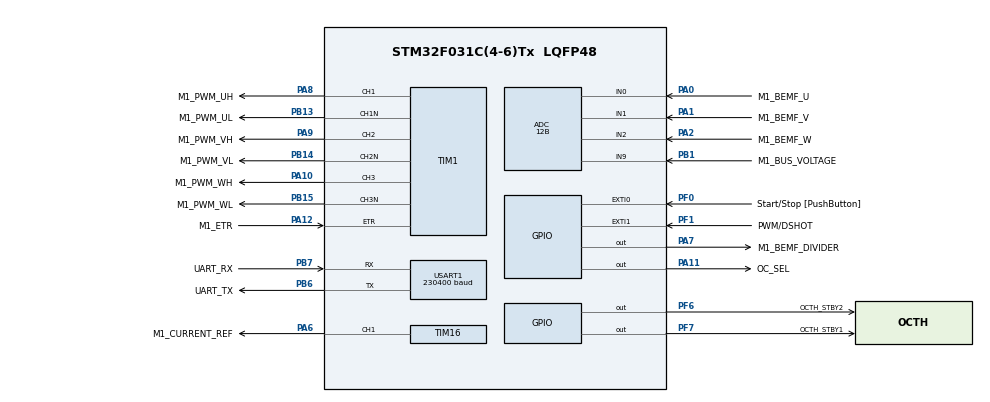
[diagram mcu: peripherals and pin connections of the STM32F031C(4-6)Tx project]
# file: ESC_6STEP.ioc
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ADC.ClockPrescaler=ADC_CLOCK_ASYNC_DIV1
ADC.ContinuousConvMode=DISABLE
ADC.DMAContinuousRequests=DISABLE
ADC.DataAlign=ADC_DATAALIGN_LEFT
ADC.DiscontinuousConvMode=DISABLE
ADC.EOCSelection=ADC_EOC_SINGLE_CONV
ADC.EnableAnalogWatchDog=true
ADC.ExternalTrigConv=ADC_EXTERNALTRIGCONV_T1_TRGO
ADC.ExternalTrigConvEdge=ADC_EXTERNALTRIGCONVEDGE_FALLING
ADC.LowPowerAutoPowerOff=DISABLE
ADC.LowPowerAutoWait=DISABLE
ADC.Overrun=ADC_OVR_DATA_PRESERVED
ADC.Resolution=ADC_RESOLUTION_12B
ADC.SamplingTime=ADC_SAMPLETIME_7CYCLES_5
ADC.ScanConvMode=ADC_SCAN_DIRECTION_FORWARD
ADC.WatchdogChannel=ADC_CHANNEL_0
ADC.WatchdogMode=ADC_ANALOGWATCHDOG_SINGLE_REG
Dma.Request0=USART1_RX
Dma.Request1=USART1_TX
Dma.USART1_RX.0.Direction=DMA_PERIPH_TO_MEMORY
Dma.USART1_RX.0.Instance=DMA1_Channel3
Dma.USART1_RX.0.MemDataAlignment=DMA_MDATAALIGN_BYTE
Dma.USART1_RX.0.MemInc=DMA_MINC_ENABLE
Dma.USART1_RX.0.Mode=DMA_NORMAL
Dma.USART1_RX.0.PeriphDataAlignment=DMA_PDATAALIGN_BYTE
Dma.USART1_RX.0.PeriphInc=DMA_PINC_DISABLE
Dma.USART1_RX.0.Priority=DMA_PRIORITY_LOW
Dma.USART1_TX.1.Direction=DMA_MEMORY_TO_PERIPH
Dma.USART1_TX.1.Instance=DMA1_Channel2
Dma.USART1_TX.1.MemDataAlignment=DMA_MDATAALIGN_BYTE
Dma.USART1_TX.1.MemInc=DMA_MINC_ENABLE
Dma.USART1_TX.1.Mode=DMA_NORMAL
Dma.USART1_TX.1.PeriphDataAlignment=DMA_PDATAALIGN_BYTE
Dma.USART1_TX.1.PeriphInc=DMA_PINC_DISABLE
Dma.USART1_TX.1.Priority=DMA_PRIORITY_LOW
ExtraMW=MotorControl
ExtraMW.MotorControl.Config=MotorControl
ExtraMW.MotorControl.Mode=MotorControl
ExtraMW.MotorControl.Root=MCSDK_v6.3.2-Full/MotorControl
ExtraMW.MotorControl.Template=templates
Mcu.Family=STM32F0
Mcu.Name=STM32F031C(4-6)Tx
Mcu.Package=LQFP48
MotorControl.ADC_REFERENCE_VOLTAGE=3.3
MotorControl.BEMF_ADC_SAMPLING_TIME=7
MotorControl.BEMF_ADC_TRIG_TIME_DPP=921
MotorControl.BEMF_ADC_TRIG_TIME_ON_DPP=256
MotorControl.BEMF_AVERAGING_FIFO_DEPTH=8
MotorControl.BEMF_DIVIDER_AVAILABLE=true
MotorControl.BEMF_DIVIDER_GPIO_PIN=LL_GPIO_PIN_7
MotorControl.BEMF_DIVIDER_GPIO_PORT=GPIOA
MotorControl.BEMF_ON_SENSING_DIVIDER=5.545455
MotorControl.BEMF_PWM_ON_ENABLE_HYSTERESIS_DPP=51
MotorControl.BEMF_PWM_ON_ENABLE_THRES_DPP=716
MotorControl.BOARD=STEVAL-SPIN3202
MotorControl.BUS_VOLTAGE_READING=true
MotorControl.CCMRAM_ENABLED=false
MotorControl.CLOCK_FREQUENCY=CPU_CLK_48_MHZ
MotorControl.CLOCK_SOURCE=INTERNAL
MotorControl.CPU_CLK_48_MHZ=true
MotorControl.CTLBOARD_NAME=STEVAL-SPIN3202
MotorControl.CUBE_MX_VER=6.8.1
MotorControl.CURRENT_LIMITER_OFFSET=true
MotorControl.CURR_REF_DIVIDER=3.2
MotorControl.CURR_REF_ETR_GPIO_PIN=LL_GPIO_PIN_12
MotorControl.CURR_REF_ETR_GPIO_PORT=GPIOA
MotorControl.CURR_REF_ETR_POLARITY=ACTIVE_HIGH
MotorControl.CURR_REF_GPIO_PIN=LL_GPIO_PIN_6
MotorControl.CURR_REF_GPIO_PORT=GPIOA
MotorControl.CURR_REF_OC_SEL_GPIO_LABEL=OC_SEL
MotorControl.CURR_REF_OC_SEL_GPIO_PIN=LL_GPIO_PIN_11
MotorControl.CURR_REF_OC_SEL_GPIO_PORT=GPIOA
MotorControl.CURR_REF_TIMER_SELECTION=TIM16
MotorControl.DEBUG_DAC_FUNCTIONALITY_EN=false
MotorControl.DRIVES_NUMBER_SELECTION=SINGLEDRIVE
MotorControl.DRIVE_MODE=CM
MotorControl.DRIVE_NUMBER=1
MotorControl.DRIVE_TYPE=SIX_STEP
MotorControl.ENCODER_AVAILABLE=false
MotorControl.ENCODER_PPR=400
MotorControl.EXT_CLOCK_FREQUENCY=INT_RC_OSC
MotorControl.FAST_DEMAG=false
MotorControl.FLASH_SIZE=32
MotorControl.HALL_SENSORS_AVAILABLE=false
MotorControl.HIGH_SIDE_IDLE_STATE=false
MotorControl.HWV_CM=InternalCurrentLimiter_PWM_IntRef
MotorControl.HWV_PWM=PoweringHighAndLowSides
MotorControl.HW_COMPLEMENTED_LOW_SIDE=false
MotorControl.HW_DEAD_TIME_NS=1000
MotorControl.INT_RC_OSC=true
MotorControl.IPs=NVIC,RCC,SYS,MotorControl,TIM1,TIM2,ADC,TIM16,USART1,DMA
MotorControl.LF_TIMER_SELECTION=LF_TIM2
MotorControl.LOW_MEMORY_FOOTPRINT_REG=false
MotorControl.LOW_SIDE_IDLE_STATE=false
MotorControl.LOW_SIDE_SIGNALS_ENABLING=LS_PWM_TIMER
MotorControl.M1_ADC_AWD_FILTER_NUMBER=0
MotorControl.M1_AMPLIFICATION_GAIN=6.6
MotorControl.M1_AUXILIARY_SPEED_SENSOR=NONE
MotorControl.M1_BEMF_THRESHOLD_PWM=50
MotorControl.M1_BEMF_THRESHOLD_PWM_HIGH=100
MotorControl.M1_BEMF_THRESHOLD_PWM_LOW=1
MotorControl.M1_BOARD_MAX_CURRENT=15
MotorControl.M1_BUS_VOLTAGE_READING=true
MotorControl.M1_COMMUTATION_STEP_TIME_BUF_SIZE=12
MotorControl.M1_COMPUTATION_DELAY=-1
MotorControl.M1_DBG_OPEN_LOOP_ENABLE=false
MotorControl.M1_DC_CURRENT_RS_MEAS=15
MotorControl.M1_DEFAULT_TARGET_SPEED_RPM=4500
MotorControl.M1_DP_TOPOLOGY=NONE
MotorControl.M1_DRIVE_TYPE=SIX_STEP
MotorControl.M1_ENABLE_SL_ALGO_FROM_PHASE=3
MotorControl.M1_ENCODER_PPR=400
MotorControl.M1_HALL_PHASE_SHIFT=300
MotorControl.M1_HALL_SENSORS_PLACEMENT=DEGREES_120
MotorControl.M1_HIGH_SIDE_IDLE_STATE=false
MotorControl.M1_HW_DEAD_TIME_NS=1000
MotorControl.M1_ICL_ENABLED=false
MotorControl.M1_ID_DEMAG=-15
MotorControl.M1_LDLQ_RATIO=1.000
MotorControl.M1_LOW_SIDE_IDLE_STATE=false
MotorControl.M1_LOW_SIDE_SIGNALS_ENABLING=LS_PWM_TIMER
MotorControl.M1_LS=0.000018
MotorControl.M1_MAX_APPLICATION_SPEED=8000
MotorControl.M1_MIN_APPLICATION_SPEED=0
MotorControl.M1_MOTOR_MAX_SPEED_RPM=8000
MotorControl.M1_MOTOR_NAME=Bull Running BR2804-1700
MotorControl.M1_MOTOR_RATED_FLUX=0.006998542
MotorControl.M1_MOTOR_VOLTAGE_CONSTANT=1.0
MotorControl.M1_NB_CONSECUTIVE_TESTS=10
MotorControl.M1_NOMINAL_BUS_VOLTAGE_V=12
MotorControl.M1_NOMINAL_CURRENT=15
MotorControl.M1_OBS_MINIMUM_SPEED_RPM=800
MotorControl.M1_OCP_TOPOLOGY=NONE
MotorControl.M1_ON_OVER_VOLTAGE=TURN_OFF_PWM
MotorControl.M1_OVP_THRESHOLD_HIGH=14
MotorControl.M1_OV_VOLTAGE_PROT_ENABLING=true
MotorControl.M1_OV_VOLTAGE_THRESHOLD_V=14
MotorControl.M1_PHASE1_DURATION=500
MotorControl.M1_PHASE1_FINAL_CURRENT=3
MotorControl.M1_PHASE1_FINAL_SPEED_RPM=0
MotorControl.M1_PHASE2_DURATION=1000
MotorControl.M1_PHASE2_FINAL_CURRENT=3
MotorControl.M1_PHASE2_FINAL_SPEED_RPM=1000
MotorControl.M1_PHASE3_DURATION=500
MotorControl.M1_PHASE3_FINAL_CURRENT=3
MotorControl.M1_PHASE3_FINAL_SPEED_RPM=1000
MotorControl.M1_PHASE4_DURATION=0
MotorControl.M1_PHASE4_FINAL_CURRENT=3
MotorControl.M1_PHASE4_FINAL_SPEED_RPM=0
MotorControl.M1_PHASE5_DURATION=0
MotorControl.M1_PHASE5_FINAL_CURRENT=3
MotorControl.M1_PHASE5_FINAL_SPEED_RPM=0
MotorControl.M1_PID_SPEED_KD_DEFAULT=0
MotorControl.M1_PID_SPEED_KI_DEFAULT=3
MotorControl.M1_PID_SPEED_KP_DEFAULT=2196
MotorControl.M1_POLE_PAIR_NUM=7
MotorControl.M1_POTENTIOMETER_ENABLE=false
MotorControl.M1_POWERBOARD_NAME=STEVAL-SPIN3202
MotorControl.M1_PWM_CHARGE_BOOT_CAP_DUTY_CYCLES=0.000
MotorControl.M1_PWM_CHARGE_BOOT_CAP_MS=10
MotorControl.M1_PWM_DRIVER_PN=STSPIN32F0A
MotorControl.M1_PWM_FREQUENCY=75000
MotorControl.M1_PWM_TIMER_BRK_IRQ=TIM1_BRK_UP_TRG_COM
MotorControl.M1_PWM_TIMER_SELECTION=PWM_TIM1
MotorControl.M1_PWM_TIMER_UP_IRQ=TIM1_BRK_UP_TRG_COM
MotorControl.M1_REGULATION_EXECUTION_RATE=2
MotorControl.M1_RS=0.11
MotorControl.M1_RSHUNT=0.01
MotorControl.M1_SHARED_SIGNAL_ENABLE=false
MotorControl.M1_SPD_DIFFERENTIAL_TERM_ENABLING=false
MotorControl.M1_SPEED_BAND_LOWER_LIMIT=15
MotorControl.M1_SPEED_BAND_UPPER_LIMIT=17
MotorControl.M1_SPEED_LOOP_FREQUENCY_HZ=1000
MotorControl.M1_SPEED_SENSOR=SENSORLESS_ADC
MotorControl.M1_SP_KDDIV=16
MotorControl.M1_SP_KIDIV=16384
MotorControl.M1_SP_KPDIV=16384
MotorControl.M1_SS_MEAS_ERRORS_BEFORE_FAULTS=3
MotorControl.M1_STARTING_ANGLE_DEG=0
MotorControl.M1_SW_DEADTIME_NS=850
MotorControl.M1_TEMPERATURE_READING=false
MotorControl.M1_TRANSITION_DURATION=25
MotorControl.M1_UD_VOLTAGE_THRESHOLD_V=7
MotorControl.M1_UV_VOLTAGE_PROT_ENABLING=true
MotorControl.M1_VBUS_ADC=ADC1
MotorControl.M1_VBUS_ADC_SAMPLING_TIME=28
MotorControl.M1_VBUS_CHANNEL=ADC_CHANNEL_9
MotorControl.M1_VBUS_PARTITIONING_FACTOR=0.052164840897235255
MotorControl.M1_ZCD_FALLING_TO_COMM=30
MotorControl.M1_ZCD_RISING_TO_COMM=30
MotorControl.MCP_ASPEP_OVER_UART=true
MotorControl.MCP_ASYNC_EN=false
MotorControl.MCP_ASYNC_OVER_ASPEP_EN=false
MotorControl.MCP_ASYNC_OVER_UART_A_EN=false
MotorControl.MCP_DMACH_RX_UART_A=3
MotorControl.MCP_DMACH_TX_UART_A=2
MotorControl.MCP_DMA_RX_UART_A=DMA1
MotorControl.MCP_DMA_TX_UART_A=DMA1
MotorControl.MCP_EN=true
MotorControl.MCP_IRQ_HANDLER_DMA_RX_UART_A=DMA1_Channel2_3_IRQHandler
MotorControl.MCP_IRQ_HANDLER_UART_A=USART1_IRQHandler
MotorControl.MCP_OVER_ASPEP_EN=true
MotorControl.MCP_OVER_STLNK_EN=false
MotorControl.MCP_OVER_UART_A_EN=true
MotorControl.MCP_OVER_UART_B_EN=false
MotorControl.MCP_RX_SYNC_PAYLOAD_MAX=128
MotorControl.MCP_TX_SYNC_PAYLOAD_MAX=128
MotorControl.MCU=STSPIN32F0A
MotorControl.MCU_FAMILY=STM32F0
MotorControl.MCU_LINE=STM32F0x1
MotorControl.MCU_NAME=STM32F031C(4-6)Tx
MotorControl.MCU_PACKAGE=LQFP48
MotorControl.MCU_TYPE=STSPIN32F0A
MotorControl.MCU_USERNAME=STM32F031C6Tx
MotorControl.MC_WORKBENCH_VERSION=6.3.2
MotorControl.MIN_DEMAG_TIME=3
MotorControl.MOTOR_TYPE=PMSM
MotorControl.OCP_INT_REF=250
MotorControl.ON_OVER_VOLTAGE=TURN_OFF_PWM
MotorControl.OV_VOLTAGE_PROT_ENABLING=true
MotorControl.PHASE_UH_GPIO_PIN=LL_GPIO_PIN_8
MotorControl.PHASE_UH_GPIO_PORT=GPIOA
MotorControl.PHASE_UH_POLARITY=H_ACTIVE_HIGH
MotorControl.PHASE_UL_GPIO_PIN=LL_GPIO_PIN_13
MotorControl.PHASE_UL_GPIO_PORT=GPIOB
MotorControl.PHASE_UL_POLARITY=L_ACTIVE_HIGH
MotorControl.PHASE_U_BEMF_ADC=ADC1
MotorControl.PHASE_U_BEMF_CHANNEL=ADC_CHANNEL_0
MotorControl.PHASE_U_BEMF_GPIO_PIN=LL_GPIO_PIN_0
MotorControl.PHASE_U_BEMF_GPIO_PORT=GPIOA
MotorControl.PHASE_U_PWM_CHANNEL=TIM_Channel_1
MotorControl.PHASE_VH_GPIO_PIN=LL_GPIO_PIN_9
MotorControl.PHASE_VH_GPIO_PORT=GPIOA
MotorControl.PHASE_VH_POLARITY=H_ACTIVE_HIGH
MotorControl.PHASE_VL_GPIO_PIN=LL_GPIO_PIN_14
MotorControl.PHASE_VL_GPIO_PORT=GPIOB
MotorControl.PHASE_VL_POLARITY=L_ACTIVE_HIGH
MotorControl.PHASE_V_BEMF_ADC=ADC1
MotorControl.PHASE_V_BEMF_CHANNEL=ADC_CHANNEL_1
MotorControl.PHASE_V_BEMF_GPIO_PIN=LL_GPIO_PIN_1
MotorControl.PHASE_V_BEMF_GPIO_PORT=GPIOA
MotorControl.PHASE_V_PWM_CHANNEL=TIM_Channel_2
MotorControl.PHASE_WH_GPIO_PIN=LL_GPIO_PIN_10
MotorControl.PHASE_WH_GPIO_PORT=GPIOA
MotorControl.PHASE_WH_POLARITY=H_ACTIVE_HIGH
MotorControl.PHASE_WL_GPIO_PIN=LL_GPIO_PIN_15
MotorControl.PHASE_WL_GPIO_PORT=GPIOB
MotorControl.PHASE_WL_POLARITY=L_ACTIVE_HIGH
MotorControl.PHASE_W_BEMF_ADC=ADC1
MotorControl.PHASE_W_BEMF_CHANNEL=ADC_CHANNEL_2
MotorControl.PHASE_W_BEMF_GPIO_PIN=LL_GPIO_PIN_2
MotorControl.PHASE_W_BEMF_GPIO_PORT=GPIOA
MotorControl.PHASE_W_PWM_CHANNEL=TIM_Channel_3
MotorControl.POTENTIOMETER_READING=false
MotorControl.PWM_FREQUENCY=75000
MotorControl.PWM_TIMER_SELECTION=PWM_TIM1
MotorControl.QUASI_SYNC=false
MotorControl.REF_TIMER_FREQUENCY=60000
MotorControl.REGULATION_EXECUTION_RATE=2
MotorControl.RUN_DEMAG_TIME=20
MotorControl.R_BRAKE_SWITCH_OFF_THRES_V=12
MotorControl.SENSORLESS_ADC=true
MotorControl.SINGLEDRIVE=true
MotorControl.SPD_DIFFERENTIAL_TERM_ENABLING=false
MotorControl.SPEED_SENSOR_SELECTION=SENSORLESS_ADC
MotorControl.SPEED_THRESHOLD_DEMAG=3000
MotorControl.STARTUP_DEMAG_TIME=20
MotorControl.START_STOP_BTN=true
MotorControl.START_STOP_GPIO_PIN=LL_GPIO_PIN_0
MotorControl.START_STOP_GPIO_PORT=GPIOF
MotorControl.START_STOP_POLARITY=DIN_ACTIVE_LOW
MotorControl.START_STOP_POLARITY_EDGE=GPIO_PULLUP
MotorControl.STSPIN32F0A=true
MotorControl.SW_DEADTIME_NS=850
MotorControl.TEMPERATURE_READING=false
MotorControl.TFDIFFERENTIAL_TERM_ENABLING=false
MotorControl.USART_RX_GPIO_PIN=LL_GPIO_PIN_7
MotorControl.USART_RX_GPIO_PORT=GPIOB
MotorControl.USART_SELECTION=USE_USART1
MotorControl.USART_SELECTION_A=USART1
MotorControl.USART_SPEED=1843200
MotorControl.USART_TX_GPIO_PIN=LL_GPIO_PIN_6
MotorControl.USART_TX_GPIO_PORT=GPIOB
MotorControl.UV_VOLTAGE_PROT_ENABLING=true
MotorControl.VBUS_ADC=ADC1
MotorControl.VBUS_ADC_SAMPLING_TIME=28
MotorControl.VBUS_CHANNEL=ADC_CHANNEL_9
MotorControl.VBUS_GPIO_PIN=LL_GPIO_PIN_1
MotorControl.VBUS_GPIO_PORT=GPIOB
MotorControl.WB_MX_ADC_AWD_FILTER_NUMBER=NONE
MotorControl.WB_MX_PHASE_U_BEMF_ADC_IRQ=ADC1
MotorControl.WB_MX_PHASE_V_BEMF_ADC_IRQ=ADC1
MotorControl.WB_MX_PHASE_W_BEMF_ADC_IRQ=ADC1
MotorControl.WB_UI_CURR_REF_TIMER_CHANNEL=CH1
MotorControl.WB_UI_ENCODER_HAS_INDEX_PIN=false
MotorControl.WB_UI_FRICTION=0.437
MotorControl.WB_UI_IMAX=22.6
MotorControl.WB_UI_INERTIA=0.348
MotorControl.WB_UI_MAGNETIC_STRUCTURE=SM-PMSM
MotorControl.WB_UI_MAX_CURRENT=15
MotorControl.WB_UI_MAX_NOMINAL_DC_VOLTAGE=12
MotorControl.WB_UI_MAX_PWMFREQUENCY=100000
MotorControl.WB_UI_MAX_READABLE_CURRENT=7.576
MotorControl.WB_UI_MOTOR_DESCRIPTION=External rotor type - 7 poles pairs brushless - DC motor
MotorControl.WB_UI_PWM_ON_SENSING=true
MotorControl.WB_UI_PW_BOARD_MAX_RATED_CURRENT=15
MotorControl.WB_UI_PW_BOARD_MAX_VOLTAGE=45
MotorControl.WB_UI_PW_BOARD_MIN_VOLTAGE=6.7
MotorControl.WB_to_Mx_template_version=24-04-17
MotorControl.WB_to_Mx_version=6.2.3
NVIC.ADC1_IRQn=true\:0\:0\:true\:true\:false\:5\:true\:true\:true
NVIC.DMA1_Channel2_3_IRQn=true\:3\:0\:true\:true\:false\:2\:true\:true\:true
NVIC.EXTI0_1_IRQn=true\:3\:0\:false\:true\:false\:6\:true\:true\:true
NVIC.TIM1_BRK_UP_TRG_COM_IRQn=true\:1\:0\:false\:true\:false\:4\:true\:true\:true
NVIC.TIM2_IRQn=true\:0\:0\:true\:true\:false\:3\:true\:true\:true
NVIC.USART1_IRQn=true\:3\:0\:true\:true\:false\:1\:true\:true\:true
PA0.GPIO_Label=M1_BEMF_U
PA0.Mode=IN0
PA0.Signal=ADC_IN0
PA1.GPIO_Label=M1_BEMF_V
PA1.Mode=IN1
PA1.Signal=ADC_IN1
PA10.GPIO_Label=M1_PWM_WH
PA10.GPIO_PuPd=GPIO_PULLDOWN
PA10.GPIO_Speed=GPIO_SPEED_FREQ_HIGH
PA10.Signal=S_TIM1_CH3
PA11.GPIO_Label=OC_SEL
PA11.GPIO_PuPd=GPIO_PULLDOWN
PA11.PinState=GPIO_PIN_SET
PA11.Signal=GPIO_Output
PA12.GPIO_Label=M1_ETR
PA12.Signal=S_TIM1_ETR
PA13.GPIO_Label=TMS
PA13.Mode=Serial_Wire
PA13.Signal=SYS_SWDIO
PA14.GPIO_Label=TCK
PA14.Mode=Serial_Wire
PA14.Signal=SYS_SWCLK
PA2.GPIO_Label=M1_BEMF_W
PA2.Mode=IN2
PA2.Signal=ADC_IN2
PA6.GPIO_Label=M1_CURRENT_REF
PA6.Signal=S_TIM16_CH1
PA7.GPIO_Label=M1_BEMF_DIVIDER
PA7.GPIO_PuPd=GPIO_PULLDOWN
PA7.PinState=GPIO_PIN_RESET
PA7.Signal=GPIO_Output
PA8.GPIO_Label=M1_PWM_UH
PA8.GPIO_PuPd=GPIO_PULLDOWN
PA8.GPIO_Speed=GPIO_SPEED_FREQ_HIGH
PA8.Signal=S_TIM1_CH1
PA9.GPIO_Label=M1_PWM_VH
PA9.GPIO_PuPd=GPIO_PULLDOWN
PA9.GPIO_Speed=GPIO_SPEED_FREQ_HIGH
PA9.Signal=S_TIM1_CH2
PB1.GPIO_Label=M1_BUS_VOLTAGE
PB1.Mode=IN9
PB1.Signal=ADC_IN9
PB13.GPIO_Label=M1_PWM_UL
PB13.GPIO_PuPd=GPIO_PULLDOWN
PB13.GPIO_Speed=GPIO_SPEED_FREQ_HIGH
PB13.Mode=PWM Generation1 CH1 CH1N
PB13.Signal=TIM1_CH1N
PB14.GPIO_Label=M1_PWM_VL
PB14.GPIO_PuPd=GPIO_PULLDOWN
PB14.GPIO_Speed=GPIO_SPEED_FREQ_HIGH
PB14.Mode=PWM Generation2 CH2 CH2N
PB14.Signal=TIM1_CH2N
PB15.GPIO_Label=M1_PWM_WL
PB15.GPIO_PuPd=GPIO_PULLDOWN
PB15.GPIO_Speed=GPIO_SPEED_FREQ_HIGH
PB15.Mode=PWM Generation3 CH3 CH3N
PB15.Signal=TIM1_CH3N
PB6.GPIO_Label=UART_TX
PB6.GPIO_Mode=GPIO_MODE_AF_PP
PB6.GPIO_PuPd=GPIO_NOPULL
PB6.GPIO_Speed=GPIO_SPEED_FREQ_LOW
PB6.Mode=Asynchronous
PB6.Signal=USART1_TX
PB7.GPIO_Label=UART_RX
PB7.GPIO_Mode=GPIO_MODE_AF_PP
PB7.GPIO_PuPd=GPIO_NOPULL
PB7.GPIO_Speed=GPIO_SPEED_FREQ_LOW
PB7.Mode=Asynchronous
PB7.Signal=USART1_RX
PF0-OSC_IN.GPIO_Label=Start/Stop [PushButton]
PF0-OSC_IN.GPIO_ModeDefaultEXTI=GPIO_MODE_IT_FALLING
PF0-OSC_IN.GPIO_PuPd=GPIO_PULLUP
PF0-OSC_IN.Signal=GPXTI0
PF1-OSC_OUT.GPIO_Label=PWM/DSHOT
PF1-OSC_OUT.GPIO_ModeDefaultEXTI=GPIO_MODE_IT_RISING_FALLING
PF1-OSC_OUT.GPIO_PuPd=GPIO_PULLDOWN
PF1-OSC_OUT.Signal=GPXTI1
PF6.GPIO_Label=OCTH_STBY2
PF6.GPIO_PuPd=GPIO_PULLDOWN
PF6.PinState=GPIO_PIN_SET
PF6.Signal=GPIO_Output
PF7.GPIO_Label=OCTH_STBY1
PF7.GPIO_PuPd=GPIO_PULLDOWN
PF7.PinState=GPIO_PIN_RESET
PF7.Signal=GPIO_Output
ProjectManager.HeapSize=0x80
ProjectManager.StackSize=0x400
ProjectManager.TargetToolchain=STM32CubeIDE
RCC.AHBFreq_Value=48000000
RCC.APB1Freq_Value=48000000
RCC.APB1TimFreq_Value=48000000
RCC.HCLKFreq_Value=48000000
RCC.PLLDivider=RCC_PREDIV_DIV2
RCC.PLLMUL=RCC_PLL_MUL12
RCC.PREFETCH_ENABLE=1
RCC.SYSCLKFreq_VALUE=48000000
RCC.SYSCLKSource=RCC_SYSCLKSOURCE_PLLCLK
SH.S_TIM16_CH1.0=TIM16_CH1,PWM Generation1 CH1
SH.S_TIM1_CH1.0=TIM1_CH1,PWM Generation1 CH1 CH1N
SH.S_TIM1_CH2.0=TIM1_CH2,PWM Generation2 CH2 CH2N
SH.S_TIM1_CH3.0=TIM1_CH3,PWM Generation3 CH3 CH3N
SH.S_TIM1_ETR.0=TIM1_ETR,ETR-as-clearing-source
TIM1.AutoReloadPreload=TIM_AUTORELOAD_PRELOAD_DISABLE
TIM1.AutomaticOutput=TIM_AUTOMATICOUTPUT_DISABLE
TIM1.BreakPolarity=TIM_BREAKPOLARITY_LOW
TIM1.BreakState=TIM_BREAK_DISABLE
TIM1.Channel-PWM\ Generation1\ CH1\ CH1N=TIM_CHANNEL_1
TIM1.Channel-PWM\ Generation2\ CH2\ CH2N=TIM_CHANNEL_2
TIM1.Channel-PWM\ Generation3\ CH3\ CH3N=TIM_CHANNEL_3
TIM1.Channel-PWM\ Generation4\ No\ Output=TIM_CHANNEL_4
TIM1.ClearChannel1=TIM_CHANNEL_1
TIM1.ClearChannel2=TIM_CHANNEL_2
TIM1.ClearChannel3=TIM_CHANNEL_3
TIM1.ClearInputPolarity=TIM_CLEARINPUTPOLARITY_NONINVERTED
TIM1.ClearInputSource=TIM_CLEARINPUTSOURCE_ETR
TIM1.ClockDivision=TIM_CLOCKDIVISION_DIV1
TIM1.CounterMode=TIM_COUNTERMODE_UP
TIM1.DeadTime=((DEAD_TIME_COUNTS) / 2)
TIM1.LockLevel=TIM_LOCKLEVEL_OFF
TIM1.OC1Preload_PWM=ENABLE
TIM1.OC2Preload_PWM=ENABLE
TIM1.OC3Preload_PWM=ENABLE
TIM1.OC4Preload_PWM=ENABLE
TIM1.OCIdleState_1=TIM_OCIDLESTATE_RESET
TIM1.OCIdleState_2=TIM_OCIDLESTATE_RESET
TIM1.OCIdleState_3=TIM_OCIDLESTATE_RESET
TIM1.OCIdleState_4=TIM_OCIDLESTATE_RESET
TIM1.OCMode_PWM-PWM\ Generation1\ CH1\ CH1N=TIM_OCMODE_PWM1
TIM1.OCMode_PWM-PWM\ Generation2\ CH2\ CH2N=TIM_OCMODE_PWM1
TIM1.OCMode_PWM-PWM\ Generation3\ CH3\ CH3N=TIM_OCMODE_PWM1
TIM1.OCMode_PWM-PWM\ Generation4\ No\ Output=TIM_OCMODE_PWM1
TIM1.OCNIdleState_1=TIM_OCNIDLESTATE_RESET
TIM1.OCNIdleState_2=TIM_OCNIDLESTATE_RESET
TIM1.OCNIdleState_3=TIM_OCNIDLESTATE_RESET
TIM1.OCNPolarity_1=TIM_OCNPOLARITY_HIGH
TIM1.OCNPolarity_2=TIM_OCNPOLARITY_HIGH
TIM1.OCNPolarity_3=TIM_OCNPOLARITY_HIGH
TIM1.OCPolarity_1=TIM_OCPOLARITY_HIGH
TIM1.OCPolarity_2=TIM_OCPOLARITY_HIGH
TIM1.OCPolarity_3=TIM_OCPOLARITY_HIGH
TIM1.OCPolarity_4=TIM_OCPOLARITY_HIGH
TIM1.OffStateIDLEMode=TIM_OSSI_ENABLE
TIM1.OffStateRunMode=TIM_OSSR_ENABLE
TIM1.Period=(PWM_PERIOD_CYCLES)
TIM1.Prescaler=((TIM_CLOCK_DIVIDER) - 1)
TIM1.RepetitionCounter=(REP_COUNTER)
TIM1.TIM_MasterOutputTrigger=TIM_TRGO_OC4REF
TIM1.TIM_MasterSlaveMode=TIM_MASTERSLAVEMODE_ENABLE
TIM16.Channel=TIM_CHANNEL_1
TIM16.Channel-PWM\ Generation1\ CH1=TIM_CHANNEL_1
TIM16.OCMode_PWM-PWM\ Generation1\ CH1=TIM_OCMODE_PWM1
TIM16.Period=PWM_PERIOD_CYCLES_REF
TIM16.Prescaler=((TIM_CLOCK_DIVIDER) - 1)
TIM2.Period=LF_TIMER_ARR
TIM2.Prescaler=LF_TIMER_PSC
TIM2.TIM_MasterOutputTrigger=TIM_TRGO_ENABLE
TIM2.TIM_MasterSlaveMode=TIM_MASTERSLAVEMODE_ENABLE
USART1.BaudRate=230400
USART1.VirtualMode-Asynchronous=VM_ASYNC
USART1.WordLength=WORDLENGTH_8B
VP_MotorControl_MC_ENABLED.Mode=SixStep
VP_TIM16_VS_ClockSourceINT.Mode=Enable_Timer
VP_TIM1_VS_no_output4.Mode=PWM Generation4 No Output
VP_TIM2_VS_ClockSourceINT.Mode=Internal
VP_TIM3_VS_ClockSourceINT.Mode=Internal
board=custom

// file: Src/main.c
/* USER CODE BEGIN Header */
/**
 ******************************************************************************
 * @file           : main.c
 * @brief          : Main program body
 ******************************************************************************
 * @attention
 *
 * Copyright (c) 2025 STMicroelectronics.
 * All rights reserved.
 *
 * This software is licensed under terms that can be found in the LICENSE file
 * in the root directory of this software component.
 * If no LICENSE file comes with this software, it is provided AS-IS.
 *
 ******************************************************************************
 */
/* USER CODE END Header */
#include "main.h"

/* USER CODE BEGIN Includes */
#include "communication.h"
#include "utils.h"
#include "interface.h"
/* USER CODE END Includes */

TIM_HandleTypeDef htim3;

void SystemClock_Config(void);
static void MX_GPIO_Init(void);
static void MX_DMA_Init(void);
static void MX_ADC_Init(void);
static void MX_TIM1_Init(void);
static void MX_TIM16_Init(void);
static void MX_TIM2_Init(void);
static void MX_USART1_UART_Init(void);
static void MX_TIM3_Init(void);
static void MX_NVIC_Init(void);

int main(void) {

	/* MCU Configuration--------------------------------------------------------*/

	/* Reset of all peripherals, Initializes the Flash interface and the Systick. */
	HAL_Init();

	/* Configure the system clock */
	SystemClock_Config();

	/* Initialize all configured peripherals */
	MX_GPIO_Init();
	MX_DMA_Init();
	MX_ADC_Init();
	MX_TIM1_Init();
	MX_TIM16_Init();
	MX_TIM2_Init();
	MX_USART1_UART_Init();
	MX_MotorControl_Init();
	MX_TIM3_Init();

	/* Initialize interrupts */
	MX_NVIC_Init();
	/* USER CODE BEGIN 2 */

	Interface_Init();
	Communication_TimerInit(PWM, &htim3);
	/* USER CODE END 2 */

	/* Infinite loop */
	while (1) {

		/* USER CODE BEGIN 3 */
		Communication_SetThrottle();
		Interface_ProcessData();
	}
	/* USER CODE END 3 */
}

void SystemClock_Config(void) {
	LL_FLASH_SetLatency(LL_FLASH_LATENCY_1);
	while (LL_FLASH_GetLatency() != LL_FLASH_LATENCY_1) {
	}
	LL_RCC_HSI_Enable();

	/* Wait till HSI is ready */
	while (LL_RCC_HSI_IsReady() != 1) {

	}
	LL_RCC_HSI_SetCalibTrimming(16);
	LL_RCC_HSI14_Enable();

	/* Wait till HSI14 is ready */
	while (LL_RCC_HSI14_IsReady() != 1) {

	}
	LL_RCC_HSI14_SetCalibTrimming(16);
	LL_RCC_PLL_ConfigDomain_SYS(LL_RCC_PLLSOURCE_HSI_DIV_2, LL_RCC_PLL_MUL_12);
	LL_RCC_PLL_Enable();

	/* Wait till PLL is ready */
	while (LL_RCC_PLL_IsReady() != 1) {

	}
	LL_RCC_SetAHBPrescaler(LL_RCC_SYSCLK_DIV_1);
	LL_RCC_SetAPB1Prescaler(LL_RCC_APB1_DIV_1);
	LL_RCC_SetSysClkSource(LL_RCC_SYS_CLKSOURCE_PLL);

	/* Wait till System clock is ready */
	while (LL_RCC_GetSysClkSource() != LL_RCC_SYS_CLKSOURCE_STATUS_PLL) {

	}
	LL_SetSystemCoreClock(48000000);

	/* Update the time base */
	if (HAL_InitTick(TICK_INT_PRIORITY) != HAL_OK) {
		Error_Handler();
	}
	LL_RCC_HSI14_EnableADCControl();
	LL_RCC_SetUSARTClockSource(LL_RCC_USART1_CLKSOURCE_PCLK1);
}

/**
 * @brief NVIC Configuration.
 * @retval None
 */
static void MX_NVIC_Init(void) {
	/* USART1_IRQn interrupt configuration */
	NVIC_SetPriority(USART1_IRQn, 3);
	NVIC_EnableIRQ(USART1_IRQn);
	/* DMA1_Channel2_3_IRQn interrupt configuration */
	NVIC_SetPriority(DMA1_Channel2_3_IRQn, 3);
	NVIC_EnableIRQ(DMA1_Channel2_3_IRQn);
	/* TIM2_IRQn interrupt configuration */
	NVIC_SetPriority(TIM2_IRQn, 0);
	NVIC_EnableIRQ(TIM2_IRQn);
	/* TIM1_BRK_UP_TRG_COM_IRQn interrupt configuration */
	NVIC_SetPriority(TIM1_BRK_UP_TRG_COM_IRQn, 1);
	NVIC_EnableIRQ(TIM1_BRK_UP_TRG_COM_IRQn);
	/* ADC1_IRQn interrupt configuration */
	NVIC_SetPriority(ADC1_IRQn, 0);
	NVIC_EnableIRQ(ADC1_IRQn);
	/* EXTI0_1_IRQn interrupt configuration */
	NVIC_SetPriority(EXTI0_1_IRQn, 3);
	NVIC_EnableIRQ(EXTI0_1_IRQn);
}

static void MX_ADC_Init(void) {

	LL_ADC_InitTypeDef ADC_InitStruct = { 0 };
	LL_ADC_REG_InitTypeDef ADC_REG_InitStruct = { 0 };

	LL_GPIO_InitTypeDef GPIO_InitStruct = { 0 };

	/* Peripheral clock enable */
	LL_APB1_GRP2_EnableClock(LL_APB1_GRP2_PERIPH_ADC1);

	LL_AHB1_GRP1_EnableClock(LL_AHB1_GRP1_PERIPH_GPIOA);
	LL_AHB1_GRP1_EnableClock(LL_AHB1_GRP1_PERIPH_GPIOB);
	/**ADC GPIO Configuration
	 PA0   ------> ADC_IN0
	 PA1   ------> ADC_IN1
	 PA2   ------> ADC_IN2
	 PB1   ------> ADC_IN9
	 */
	GPIO_InitStruct.Pin = M1_BEMF_U_Pin;
	GPIO_InitStruct.Mode = LL_GPIO_MODE_ANALOG;
	GPIO_InitStruct.Pull = LL_GPIO_PULL_NO;
	LL_GPIO_Init(M1_BEMF_U_GPIO_Port, &GPIO_InitStruct);

	GPIO_InitStruct.Pin = M1_BEMF_V_Pin;
	GPIO_InitStruct.Mode = LL_GPIO_MODE_ANALOG;
	GPIO_InitStruct.Pull = LL_GPIO_PULL_NO;
	LL_GPIO_Init(M1_BEMF_V_GPIO_Port, &GPIO_InitStruct);

	GPIO_InitStruct.Pin = M1_BEMF_W_Pin;
	GPIO_InitStruct.Mode = LL_GPIO_MODE_ANALOG;
	GPIO_InitStruct.Pull = LL_GPIO_PULL_NO;
	LL_GPIO_Init(M1_BEMF_W_GPIO_Port, &GPIO_InitStruct);

	GPIO_InitStruct.Pin = M1_BUS_VOLTAGE_Pin;
	GPIO_InitStruct.Mode = LL_GPIO_MODE_ANALOG;
	GPIO_InitStruct.Pull = LL_GPIO_PULL_NO;
	LL_GPIO_Init(M1_BUS_VOLTAGE_GPIO_Port, &GPIO_InitStruct);

	/** Configure Regular Channel
	 */
	LL_ADC_REG_SetSequencerChAdd(ADC1, LL_ADC_CHANNEL_0);

	/** Configure Regular Channel
	 */
	LL_ADC_REG_SetSequencerChAdd(ADC1, LL_ADC_CHANNEL_1);

	/** Configure Regular Channel
	 */
	LL_ADC_REG_SetSequencerChAdd(ADC1, LL_ADC_CHANNEL_2);

	/** Configure Regular Channel
	 */
	LL_ADC_REG_SetSequencerChAdd(ADC1, LL_ADC_CHANNEL_9);

	/** Configure the global features of the ADC (Clock, Resolution, Data Alignment and number of conversion)
	 */
	ADC_InitStruct.Clock = LL_ADC_CLOCK_ASYNC;
	ADC_InitStruct.Resolution = LL_ADC_RESOLUTION_12B;
	ADC_InitStruct.DataAlignment = LL_ADC_DATA_ALIGN_LEFT;
	ADC_InitStruct.LowPowerMode = LL_ADC_LP_MODE_NONE;
	LL_ADC_Init(ADC1, &ADC_InitStruct);
	ADC_REG_InitStruct.TriggerSource = LL_ADC_REG_TRIG_EXT_TIM1_TRGO;
	ADC_REG_InitStruct.SequencerDiscont = LL_ADC_REG_SEQ_DISCONT_DISABLE;
	ADC_REG_InitStruct.ContinuousMode = LL_ADC_REG_CONV_SINGLE;
	ADC_REG_InitStruct.DMATransfer = LL_ADC_REG_DMA_TRANSFER_LIMITED;
	ADC_REG_InitStruct.Overrun = LL_ADC_REG_OVR_DATA_PRESERVED;
	LL_ADC_REG_Init(ADC1, &ADC_REG_InitStruct);
	LL_ADC_REG_SetSequencerScanDirection(ADC1, LL_ADC_REG_SEQ_SCAN_DIR_FORWARD);
	LL_ADC_SetSamplingTimeCommonChannels(ADC1, LL_ADC_SAMPLINGTIME_7CYCLES_5);
	LL_ADC_REG_SetTriggerEdge(ADC1, LL_ADC_REG_TRIG_EXT_FALLING);

	/** Configure Analog WatchDog
	 */
	LL_ADC_SetAnalogWDMonitChannels(ADC1, LL_ADC_AWD_CHANNEL_0_REG);
	LL_ADC_ConfigAnalogWDThresholds(ADC1, 0, 0);
	LL_ADC_DisableIT_AWD1(ADC1);

}

static void MX_TIM1_Init(void) {

	LL_TIM_InitTypeDef TIM_InitStruct = { 0 };
	LL_TIM_OC_InitTypeDef TIM_OC_InitStruct = { 0 };
	LL_TIM_BDTR_InitTypeDef TIM_BDTRInitStruct = { 0 };

	LL_GPIO_InitTypeDef GPIO_InitStruct = { 0 };

	/* Peripheral clock enable */
	LL_APB1_GRP2_EnableClock(LL_APB1_GRP2_PERIPH_TIM1);

	LL_AHB1_GRP1_EnableClock(LL_AHB1_GRP1_PERIPH_GPIOA);
	/**TIM1 GPIO Configuration
	 PA12   ------> TIM1_ETR
	 */
	GPIO_InitStruct.Pin = M1_ETR_Pin;
	GPIO_InitStruct.Mode = LL_GPIO_MODE_ALTERNATE;
	GPIO_InitStruct.Speed = LL_GPIO_SPEED_FREQ_LOW;
	GPIO_InitStruct.OutputType = LL_GPIO_OUTPUT_PUSHPULL;
	GPIO_InitStruct.Pull = LL_GPIO_PULL_NO;
	GPIO_InitStruct.Alternate = LL_GPIO_AF_2;
	LL_GPIO_Init(M1_ETR_GPIO_Port, &GPIO_InitStruct);

	TIM_InitStruct.Prescaler = ((TIM_CLOCK_DIVIDER) - 1);
	TIM_InitStruct.CounterMode = LL_TIM_COUNTERMODE_UP;
	TIM_InitStruct.Autoreload = (PWM_PERIOD_CYCLES );
	TIM_InitStruct.ClockDivision = LL_TIM_CLOCKDIVISION_DIV1;
	TIM_InitStruct.RepetitionCounter = (REP_COUNTER );
	LL_TIM_Init(TIM1, &TIM_InitStruct);
	LL_TIM_DisableARRPreload(TIM1);
	LL_TIM_OC_EnablePreload(TIM1, LL_TIM_CHANNEL_CH1);
	TIM_OC_InitStruct.OCMode = LL_TIM_OCMODE_PWM1;
	TIM_OC_InitStruct.OCState = LL_TIM_OCSTATE_DISABLE;
	TIM_OC_InitStruct.OCNState = LL_TIM_OCSTATE_DISABLE;
	TIM_OC_InitStruct.CompareValue = 0;
	TIM_OC_InitStruct.OCPolarity = LL_TIM_OCPOLARITY_HIGH;
	TIM_OC_InitStruct.OCNPolarity = LL_TIM_OCPOLARITY_HIGH;
	TIM_OC_InitStruct.OCIdleState = LL_TIM_OCIDLESTATE_LOW;
	TIM_OC_InitStruct.OCNIdleState = LL_TIM_OCIDLESTATE_LOW;
	LL_TIM_OC_Init(TIM1, LL_TIM_CHANNEL_CH1, &TIM_OC_InitStruct);
	LL_TIM_OC_DisableFast(TIM1, LL_TIM_CHANNEL_CH1);
	LL_TIM_OC_EnablePreload(TIM1, LL_TIM_CHANNEL_CH2);
	LL_TIM_OC_Init(TIM1, LL_TIM_CHANNEL_CH2, &TIM_OC_InitStruct);
	LL_TIM_OC_DisableFast(TIM1, LL_TIM_CHANNEL_CH2);
	LL_TIM_OC_EnablePreload(TIM1, LL_TIM_CHANNEL_CH3);
	LL_TIM_OC_Init(TIM1, LL_TIM_CHANNEL_CH3, &TIM_OC_InitStruct);
	LL_TIM_OC_DisableFast(TIM1, LL_TIM_CHANNEL_CH3);
	LL_TIM_OC_EnablePreload(TIM1, LL_TIM_CHANNEL_CH4);
	LL_TIM_OC_Init(TIM1, LL_TIM_CHANNEL_CH4, &TIM_OC_InitStruct);
	LL_TIM_OC_DisableFast(TIM1, LL_TIM_CHANNEL_CH4);
	LL_TIM_SetOCRefClearInputSource(TIM1, LL_TIM_OCREF_CLR_INT_ETR);
	LL_TIM_DisableExternalClock(TIM1);
	LL_TIM_ConfigETR(TIM1, LL_TIM_ETR_POLARITY_NONINVERTED, LL_TIM_ETR_PRESCALER_DIV1, LL_TIM_ETR_FILTER_FDIV1);
	LL_TIM_OC_EnableClear(TIM1, LL_TIM_CHANNEL_CH1);
	LL_TIM_OC_EnableClear(TIM1, LL_TIM_CHANNEL_CH2);
	LL_TIM_OC_EnableClear(TIM1, LL_TIM_CHANNEL_CH3);
	LL_TIM_SetTriggerOutput(TIM1, LL_TIM_TRGO_OC4REF);
	LL_TIM_EnableMasterSlaveMode(TIM1);
	TIM_BDTRInitStruct.OSSRState = LL_TIM_OSSR_ENABLE;
	TIM_BDTRInitStruct.OSSIState = LL_TIM_OSSI_ENABLE;
	TIM_BDTRInitStruct.LockLevel = LL_TIM_LOCKLEVEL_OFF;
	TIM_BDTRInitStruct.DeadTime = ((DEAD_TIME_COUNTS ) / 2);
	TIM_BDTRInitStruct.BreakState = LL_TIM_BREAK_DISABLE;
	TIM_BDTRInitStruct.BreakPolarity = LL_TIM_BREAK_POLARITY_LOW;
	TIM_BDTRInitStruct.AutomaticOutput = LL_TIM_AUTOMATICOUTPUT_DISABLE;
	LL_TIM_BDTR_Init(TIM1, &TIM_BDTRInitStruct);
	LL_AHB1_GRP1_EnableClock(LL_AHB1_GRP1_PERIPH_GPIOB);
	LL_AHB1_GRP1_EnableClock(LL_AHB1_GRP1_PERIPH_GPIOA);
	/**TIM1 GPIO Configuration
	 PB13   ------> TIM1_CH1N
	 PB14   ------> TIM1_CH2N
	 PB15   ------> TIM1_CH3N
	 PA8   ------> TIM1_CH1
	 PA9   ------> TIM1_CH2
	 PA10   ------> TIM1_CH3
	 */
	GPIO_InitStruct.Pin = M1_PWM_UL_Pin;
	GPIO_InitStruct.Mode = LL_GPIO_MODE_ALTERNATE;
	GPIO_InitStruct.Speed = LL_GPIO_SPEED_FREQ_HIGH;
	GPIO_InitStruct.OutputType = LL_GPIO_OUTPUT_PUSHPULL;
	GPIO_InitStruct.Pull = LL_GPIO_PULL_DOWN;
	GPIO_InitStruct.Alternate = LL_GPIO_AF_2;
	LL_GPIO_Init(M1_PWM_UL_GPIO_Port, &GPIO_InitStruct);

	GPIO_InitStruct.Pin = M1_PWM_VL_Pin;
	GPIO_InitStruct.Mode = LL_GPIO_MODE_ALTERNATE;
	GPIO_InitStruct.Speed = LL_GPIO_SPEED_FREQ_HIGH;
	GPIO_InitStruct.OutputType = LL_GPIO_OUTPUT_PUSHPULL;
	GPIO_InitStruct.Pull = LL_GPIO_PULL_DOWN;
	GPIO_InitStruct.Alternate = LL_GPIO_AF_2;
	LL_GPIO_Init(M1_PWM_VL_GPIO_Port, &GPIO_InitStruct);

	GPIO_InitStruct.Pin = M1_PWM_WL_Pin;
	GPIO_InitStruct.Mode = LL_GPIO_MODE_ALTERNATE;
	GPIO_InitStruct.Speed = LL_GPIO_SPEED_FREQ_HIGH;
	GPIO_InitStruct.OutputType = LL_GPIO_OUTPUT_PUSHPULL;
	GPIO_InitStruct.Pull = LL_GPIO_PULL_DOWN;
	GPIO_InitStruct.Alternate = LL_GPIO_AF_2;
	LL_GPIO_Init(M1_PWM_WL_GPIO_Port, &GPIO_InitStruct);

	GPIO_InitStruct.Pin = M1_PWM_UH_Pin;
	GPIO_InitStruct.Mode = LL_GPIO_MODE_ALTERNATE;
	GPIO_InitStruct.Speed = LL_GPIO_SPEED_FREQ_HIGH;
	GPIO_InitStruct.OutputType = LL_GPIO_OUTPUT_PUSHPULL;
	GPIO_InitStruct.Pull = LL_GPIO_PULL_DOWN;
	GPIO_InitStruct.Alternate = LL_GPIO_AF_2;
	LL_GPIO_Init(M1_PWM_UH_GPIO_Port, &GPIO_InitStruct);

	GPIO_InitStruct.Pin = M1_PWM_VH_Pin;
	GPIO_InitStruct.Mode = LL_GPIO_MODE_ALTERNATE;
	GPIO_InitStruct.Speed = LL_GPIO_SPEED_FREQ_HIGH;
	GPIO_InitStruct.OutputType = LL_GPIO_OUTPUT_PUSHPULL;
	GPIO_InitStruct.Pull = LL_GPIO_PULL_DOWN;
	GPIO_InitStruct.Alternate = LL_GPIO_AF_2;
	LL_GPIO_Init(M1_PWM_VH_GPIO_Port, &GPIO_InitStruct);

	GPIO_InitStruct.Pin = M1_PWM_WH_Pin;
	GPIO_InitStruct.Mode = LL_GPIO_MODE_ALTERNATE;
	GPIO_InitStruct.Speed = LL_GPIO_SPEED_FREQ_HIGH;
	GPIO_InitStruct.OutputType = LL_GPIO_OUTPUT_PUSHPULL;
	GPIO_InitStruct.Pull = LL_GPIO_PULL_DOWN;
	GPIO_InitStruct.Alternate = LL_GPIO_AF_2;
	LL_GPIO_Init(M1_PWM_WH_GPIO_Port, &GPIO_InitStruct);

}

static void MX_TIM2_Init(void) {

	LL_TIM_InitTypeDef TIM_InitStruct = { 0 };

	/* Peripheral clock enable */
	LL_APB1_GRP1_EnableClock(LL_APB1_GRP1_PERIPH_TIM2);

	TIM_InitStruct.Prescaler = LF_TIMER_PSC;
	TIM_InitStruct.CounterMode = LL_TIM_COUNTERMODE_UP;
	TIM_InitStruct.Autoreload = LF_TIMER_ARR;
	TIM_InitStruct.ClockDivision = LL_TIM_CLOCKDIVISION_DIV1;
	LL_TIM_Init(TIM2, &TIM_InitStruct);
	LL_TIM_DisableARRPreload(TIM2);
	LL_TIM_SetClockSource(TIM2, LL_TIM_CLOCKSOURCE_INTERNAL);
	LL_TIM_SetTriggerOutput(TIM2, LL_TIM_TRGO_ENABLE);
	LL_TIM_EnableMasterSlaveMode(TIM2);

}

static void MX_TIM3_Init(void) {

	TIM_ClockConfigTypeDef sClockSourceConfig = { 0 };
	TIM_MasterConfigTypeDef sMasterConfig = { 0 };

	htim3.Instance = TIM3;
	htim3.Init.Prescaler = 0;
	htim3.Init.CounterMode = TIM_COUNTERMODE_UP;
	htim3.Init.Period = 65535;
	htim3.Init.ClockDivision = TIM_CLOCKDIVISION_DIV1;
	htim3.Init.AutoReloadPreload = TIM_AUTORELOAD_PRELOAD_DISABLE;
	if (HAL_TIM_Base_Init(&htim3) != HAL_OK) {
		Error_Handler();
	}
	sClockSourceConfig.ClockSource = TIM_CLOCKSOURCE_INTERNAL;
	if (HAL_TIM_ConfigClockSource(&htim3, &sClockSourceConfig) != HAL_OK) {
		Error_Handler();
	}
	sMasterConfig.MasterOutputTrigger = TIM_TRGO_RESET;
	sMasterConfig.MasterSlaveMode = TIM_MASTERSLAVEMODE_DISABLE;
	if (HAL_TIMEx_MasterConfigSynchronization(&htim3, &sMasterConfig) != HAL_OK) {
		Error_Handler();
	}

}

static void MX_TIM16_Init(void) {

	LL_TIM_InitTypeDef TIM_InitStruct = { 0 };
	LL_TIM_OC_InitTypeDef TIM_OC_InitStruct = { 0 };
	LL_TIM_BDTR_InitTypeDef TIM_BDTRInitStruct = { 0 };

	LL_GPIO_InitTypeDef GPIO_InitStruct = { 0 };

	/* Peripheral clock enable */
	LL_APB1_GRP2_EnableClock(LL_APB1_GRP2_PERIPH_TIM16);

	TIM_InitStruct.Prescaler = ((TIM_CLOCK_DIVIDER) - 1);
	TIM_InitStruct.CounterMode = LL_TIM_COUNTERMODE_UP;
	TIM_InitStruct.Autoreload = PWM_PERIOD_CYCLES_REF;
	TIM_InitStruct.ClockDivision = LL_TIM_CLOCKDIVISION_DIV1;
	TIM_InitStruct.RepetitionCounter = 0;
	LL_TIM_Init(TIM16, &TIM_InitStruct);
	LL_TIM_DisableARRPreload(TIM16);
	LL_TIM_OC_EnablePreload(TIM16, LL_TIM_CHANNEL_CH1);
	TIM_OC_InitStruct.OCMode = LL_TIM_OCMODE_PWM1;
	TIM_OC_InitStruct.OCState = LL_TIM_OCSTATE_DISABLE;
	TIM_OC_InitStruct.OCNState = LL_TIM_OCSTATE_DISABLE;
	TIM_OC_InitStruct.CompareValue = 0;
	TIM_OC_InitStruct.OCPolarity = LL_TIM_OCPOLARITY_HIGH;
	TIM_OC_InitStruct.OCNPolarity = LL_TIM_OCPOLARITY_HIGH;
	TIM_OC_InitStruct.OCIdleState = LL_TIM_OCIDLESTATE_LOW;
	TIM_OC_InitStruct.OCNIdleState = LL_TIM_OCIDLESTATE_LOW;
	LL_TIM_OC_Init(TIM16, LL_TIM_CHANNEL_CH1, &TIM_OC_InitStruct);
	LL_TIM_OC_DisableFast(TIM16, LL_TIM_CHANNEL_CH1);
	TIM_BDTRInitStruct.OSSRState = LL_TIM_OSSR_DISABLE;
	TIM_BDTRInitStruct.OSSIState = LL_TIM_OSSI_DISABLE;
	TIM_BDTRInitStruct.LockLevel = LL_TIM_LOCKLEVEL_OFF;
	TIM_BDTRInitStruct.DeadTime = 0;
	TIM_BDTRInitStruct.BreakState = LL_TIM_BREAK_DISABLE;
	TIM_BDTRInitStruct.BreakPolarity = LL_TIM_BREAK_POLARITY_HIGH;
	TIM_BDTRInitStruct.AutomaticOutput = LL_TIM_AUTOMATICOUTPUT_DISABLE;
	LL_TIM_BDTR_Init(TIM16, &TIM_BDTRInitStruct);
	LL_AHB1_GRP1_EnableClock(LL_AHB1_GRP1_PERIPH_GPIOA);
	/**TIM16 GPIO Configuration
	 PA6   ------> TIM16_CH1
	 */
	GPIO_InitStruct.Pin = M1_CURRENT_REF_Pin;
	GPIO_InitStruct.Mode = LL_GPIO_MODE_ALTERNATE;
	GPIO_InitStruct.Speed = LL_GPIO_SPEED_FREQ_LOW;
	GPIO_InitStruct.OutputType = LL_GPIO_OUTPUT_PUSHPULL;
	GPIO_InitStruct.Pull = LL_GPIO_PULL_NO;
	GPIO_InitStruct.Alternate = LL_GPIO_AF_5;
	LL_GPIO_Init(M1_CURRENT_REF_GPIO_Port, &GPIO_InitStruct);

}

static void MX_USART1_UART_Init(void) {

	LL_USART_InitTypeDef USART_InitStruct = { 0 };

	LL_GPIO_InitTypeDef GPIO_InitStruct = { 0 };

	/* Peripheral clock enable */
	LL_APB1_GRP2_EnableClock(LL_APB1_GRP2_PERIPH_USART1);

	LL_AHB1_GRP1_EnableClock(LL_AHB1_GRP1_PERIPH_GPIOB);
	/**USART1 GPIO Configuration
	 PB6   ------> USART1_TX
	 PB7   ------> USART1_RX
	 */
	GPIO_InitStruct.Pin = UART_TX_Pin;
	GPIO_InitStruct.Mode = LL_GPIO_MODE_ALTERNATE;
	GPIO_InitStruct.Speed = LL_GPIO_SPEED_FREQ_LOW;
	GPIO_InitStruct.OutputType = LL_GPIO_OUTPUT_PUSHPULL;
	GPIO_InitStruct.Pull = LL_GPIO_PULL_NO;
	GPIO_InitStruct.Alternate = LL_GPIO_AF_0;
	LL_GPIO_Init(UART_TX_GPIO_Port, &GPIO_InitStruct);

	GPIO_InitStruct.Pin = UART_RX_Pin;
	GPIO_InitStruct.Mode = LL_GPIO_MODE_ALTERNATE;
	GPIO_InitStruct.Speed = LL_GPIO_SPEED_FREQ_LOW;
	GPIO_InitStruct.OutputType = LL_GPIO_OUTPUT_PUSHPULL;
	GPIO_InitStruct.Pull = LL_GPIO_PULL_NO;
	GPIO_InitStruct.Alternate = LL_GPIO_AF_0;
	LL_GPIO_Init(UART_RX_GPIO_Port, &GPIO_InitStruct);

	/* USART1 DMA Init */

	/* USART1_RX Init */
	LL_DMA_SetDataTransferDirection(DMA1, LL_DMA_CHANNEL_3, LL_DMA_DIRECTION_PERIPH_TO_MEMORY);

	LL_DMA_SetChannelPriorityLevel(DMA1, LL_DMA_CHANNEL_3, LL_DMA_PRIORITY_LOW);

	LL_DMA_SetMode(DMA1, LL_DMA_CHANNEL_3, LL_DMA_MODE_NORMAL);

	LL_DMA_SetPeriphIncMode(DMA1, LL_DMA_CHANNEL_3, LL_DMA_PERIPH_NOINCREMENT);

	LL_DMA_SetMemoryIncMode(DMA1, LL_DMA_CHANNEL_3, LL_DMA_MEMORY_INCREMENT);

	LL_DMA_SetPeriphSize(DMA1, LL_DMA_CHANNEL_3, LL_DMA_PDATAALIGN_BYTE);

	LL_DMA_SetMemorySize(DMA1, LL_DMA_CHANNEL_3, LL_DMA_MDATAALIGN_BYTE);

	/* USART1_TX Init */
	LL_DMA_SetDataTransferDirection(DMA1, LL_DMA_CHANNEL_2, LL_DMA_DIRECTION_MEMORY_TO_PERIPH);

	LL_DMA_SetChannelPriorityLevel(DMA1, LL_DMA_CHANNEL_2, LL_DMA_PRIORITY_LOW);

	LL_DMA_SetMode(DMA1, LL_DMA_CHANNEL_2, LL_DMA_MODE_NORMAL);

	LL_DMA_SetPeriphIncMode(DMA1, LL_DMA_CHANNEL_2, LL_DMA_PERIPH_NOINCREMENT);

	LL_DMA_SetMemoryIncMode(DMA1, LL_DMA_CHANNEL_2, LL_DMA_MEMORY_INCREMENT);

	LL_DMA_SetPeriphSize(DMA1, LL_DMA_CHANNEL_2, LL_DMA_PDATAALIGN_BYTE);

	LL_DMA_SetMemorySize(DMA1, LL_DMA_CHANNEL_2, LL_DMA_MDATAALIGN_BYTE);

	USART_InitStruct.BaudRate = 230400;
	USART_InitStruct.DataWidth = LL_USART_DATAWIDTH_8B;
	USART_InitStruct.StopBits = LL_USART_STOPBITS_1;
	USART_InitStruct.Parity = LL_USART_PARITY_NONE;
	USART_InitStruct.TransferDirection = LL_USART_DIRECTION_TX_RX;
	USART_InitStruct.HardwareFlowControl = LL_USART_HWCONTROL_NONE;
	USART_InitStruct.OverSampling = LL_USART_OVERSAMPLING_16;
	LL_USART_Init(USART1, &USART_InitStruct);
	LL_USART_DisableIT_CTS(USART1);
	LL_USART_ConfigAsyncMode(USART1);
	LL_USART_Enable(USART1);

}

static void MX_DMA_Init(void) {

	/* Init with LL driver */
	/* DMA controller clock enable */
	LL_AHB1_GRP1_EnableClock(LL_AHB1_GRP1_PERIPH_DMA1);

}

static void MX_GPIO_Init(void) {
	LL_EXTI_InitTypeDef EXTI_InitStruct = { 0 };
	LL_GPIO_InitTypeDef GPIO_InitStruct = { 0 };

	/* GPIO Ports Clock Enable */
	LL_AHB1_GRP1_EnableClock(LL_AHB1_GRP1_PERIPH_GPIOF);
	LL_AHB1_GRP1_EnableClock(LL_AHB1_GRP1_PERIPH_GPIOA);
	LL_AHB1_GRP1_EnableClock(LL_AHB1_GRP1_PERIPH_GPIOB);

	/**/
	LL_GPIO_ResetOutputPin(M1_BEMF_DIVIDER_GPIO_Port, M1_BEMF_DIVIDER_Pin);

	/**/
	LL_GPIO_ResetOutputPin(OCTH_STBY1_GPIO_Port, OCTH_STBY1_Pin);

	/**/
	LL_GPIO_SetOutputPin(OC_SEL_GPIO_Port, OC_SEL_Pin);

	/**/
	LL_GPIO_SetOutputPin(OCTH_STBY2_GPIO_Port, OCTH_STBY2_Pin);

	/**/
	LL_SYSCFG_SetEXTISource(LL_SYSCFG_EXTI_PORTF, LL_SYSCFG_EXTI_LINE0);

	/**/
	LL_SYSCFG_SetEXTISource(LL_SYSCFG_EXTI_PORTF, LL_SYSCFG_EXTI_LINE1);

	/**/
	LL_GPIO_SetPinPull(Start_Stop_GPIO_Port, Start_Stop_Pin, LL_GPIO_PULL_UP);

	/**/
	LL_GPIO_SetPinPull(PWM_DSHOT_GPIO_Port, PWM_DSHOT_Pin, LL_GPIO_PULL_DOWN);

	/**/
	LL_GPIO_SetPinMode(Start_Stop_GPIO_Port, Start_Stop_Pin, LL_GPIO_MODE_INPUT);

	/**/
	LL_GPIO_SetPinMode(PWM_DSHOT_GPIO_Port, PWM_DSHOT_Pin, LL_GPIO_MODE_INPUT);

	/**/
	EXTI_InitStruct.Line_0_31 = LL_EXTI_LINE_0;
	EXTI_InitStruct.LineCommand = ENABLE;
	EXTI_InitStruct.Mode = LL_EXTI_MODE_IT;
	EXTI_InitStruct.Trigger = LL_EXTI_TRIGGER_FALLING;
	LL_EXTI_Init(&EXTI_InitStruct);

	/**/
	EXTI_InitStruct.Line_0_31 = LL_EXTI_LINE_1;
	EXTI_InitStruct.LineCommand = ENABLE;
	EXTI_InitStruct.Mode = LL_EXTI_MODE_IT;
	EXTI_InitStruct.Trigger = LL_EXTI_TRIGGER_RISING_FALLING;
	LL_EXTI_Init(&EXTI_InitStruct);

	/**/
	GPIO_InitStruct.Pin = M1_BEMF_DIVIDER_Pin;
	GPIO_InitStruct.Mode = LL_GPIO_MODE_OUTPUT;
	GPIO_InitStruct.Speed = LL_GPIO_SPEED_FREQ_LOW;
	GPIO_InitStruct.OutputType = LL_GPIO_OUTPUT_PUSHPULL;
	GPIO_InitStruct.Pull = LL_GPIO_PULL_DOWN;
	LL_GPIO_Init(M1_BEMF_DIVIDER_GPIO_Port, &GPIO_InitStruct);

	/**/
	GPIO_InitStruct.Pin = OC_SEL_Pin;
	GPIO_InitStruct.Mode = LL_GPIO_MODE_OUTPUT;
	GPIO_InitStruct.Speed = LL_GPIO_SPEED_FREQ_LOW;
	GPIO_InitStruct.OutputType = LL_GPIO_OUTPUT_PUSHPULL;
	GPIO_InitStruct.Pull = LL_GPIO_PULL_DOWN;
	LL_GPIO_Init(OC_SEL_GPIO_Port, &GPIO_InitStruct);

	/**/
	GPIO_InitStruct.Pin = OCTH_STBY2_Pin;
	GPIO_InitStruct.Mode = LL_GPIO_MODE_OUTPUT;
	GPIO_InitStruct.Speed = LL_GPIO_SPEED_FREQ_LOW;
	GPIO_InitStruct.OutputType = LL_GPIO_OUTPUT_PUSHPULL;
	GPIO_InitStruct.Pull = LL_GPIO_PULL_DOWN;
	LL_GPIO_Init(OCTH_STBY2_GPIO_Port, &GPIO_InitStruct);

	/**/
	GPIO_InitStruct.Pin = OCTH_STBY1_Pin;
	GPIO_InitStruct.Mode = LL_GPIO_MODE_OUTPUT;
	GPIO_InitStruct.Speed = LL_GPIO_SPEED_FREQ_LOW;
	GPIO_InitStruct.OutputType = LL_GPIO_OUTPUT_PUSHPULL;
	GPIO_InitStruct.Pull = LL_GPIO_PULL_DOWN;
	LL_GPIO_Init(OCTH_STBY1_GPIO_Port, &GPIO_InitStruct);

	/* USER CODE BEGIN MX_GPIO_Init_2 */
	// Enable RXNE interrupt to receive data without DMA
//	LL_USART_EnableIT_RXNE(USART1);
	/* USER CODE END MX_GPIO_Init_2 */
}

void Error_Handler(void) {
	__disable_irq();
	while (1) {
	}
}
